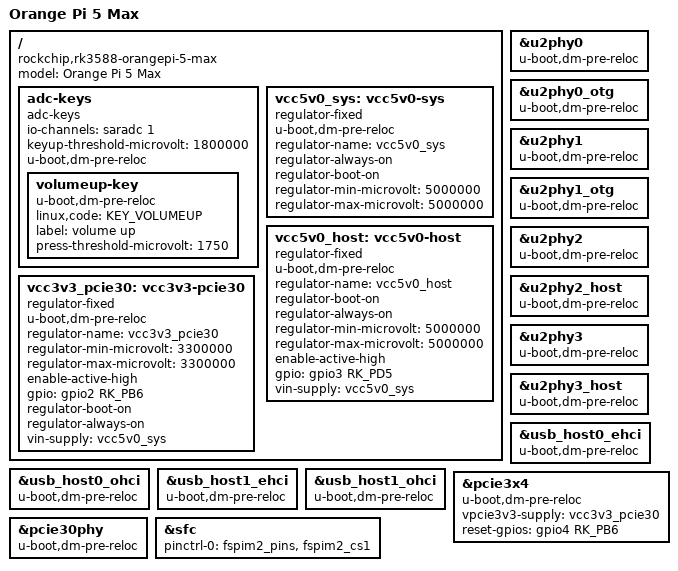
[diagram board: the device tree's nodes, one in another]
// SPDX-License-Identifier: (GPL-2.0+ OR MIT)
/*
 * Copyright (c) 2021 Rockchip Electronics Co., Ltd
 *
 */

/dts-v1/;
#include "rk3588.dtsi"
#include "rk3588-u-boot.dtsi"
#include <dt-bindings/input/input.h>

/ {
	model = "Orange Pi 5 Max";
	compatible = "rockchip,rk3588-orangepi-5-max", "rockchip,rk3588";

	adc-keys {
		compatible = "adc-keys";
		io-channels = <&saradc 1>;
		io-channel-names = "buttons";
		keyup-threshold-microvolt = <1800000>;
		u-boot,dm-pre-reloc;
		status = "okay";

		volumeup-key {
			u-boot,dm-pre-reloc;
			linux,code = <KEY_VOLUMEUP>;
			label = "volume up";
			press-threshold-microvolt = <1750>;
		};
	};

	vcc5v0_sys: vcc5v0-sys {
		u-boot,dm-pre-reloc;
		compatible = "regulator-fixed";
		regulator-name = "vcc5v0_sys";
		regulator-always-on;
		regulator-boot-on;
		regulator-min-microvolt = <5000000>;
		regulator-max-microvolt = <5000000>;
	};

	vcc5v0_host: vcc5v0-host {
		u-boot,dm-pre-reloc;
		compatible = "regulator-fixed";
		regulator-name = "vcc5v0_host";
		regulator-boot-on;
		regulator-always-on;
		regulator-min-microvolt = <5000000>;
		regulator-max-microvolt = <5000000>;
		enable-active-high;
		gpio = <&gpio3 RK_PD5 GPIO_ACTIVE_HIGH>;
		vin-supply = <&vcc5v0_sys>;
	};

	vcc3v3_pcie30: vcc3v3-pcie30 {
		u-boot,dm-pre-reloc;
		compatible = "regulator-fixed";
		regulator-name = "vcc3v3_pcie30";
		regulator-min-microvolt = <3300000>;
		regulator-max-microvolt = <3300000>;
		enable-active-high;
		gpio = <&gpio2 RK_PB6 GPIO_ACTIVE_HIGH>;
		regulator-boot-on;
		regulator-always-on;
		vin-supply = <&vcc5v0_sys>;
	};
};

&u2phy0 {
	u-boot,dm-pre-reloc;
	status = "okay";
};

&u2phy0_otg {
	u-boot,dm-pre-reloc;
	status = "okay";
};

&u2phy1 {
	u-boot,dm-pre-reloc;
	status = "okay";
};

&u2phy1_otg {
	u-boot,dm-pre-reloc;
	status = "okay";
};

&u2phy2 {
	u-boot,dm-pre-reloc;
	status = "okay";
};

&u2phy2_host {
	u-boot,dm-pre-reloc;
	status = "okay";
};

&u2phy3 {
	u-boot,dm-pre-reloc;
	status = "okay";
};

&u2phy3_host {
	u-boot,dm-pre-reloc;
	status = "okay";
};

&usb_host0_ehci {
	u-boot,dm-pre-reloc;
	status = "okay";
};

&usb_host0_ohci {
	u-boot,dm-pre-reloc;
	status = "okay";
};

&usb_host1_ehci {
	u-boot,dm-pre-reloc;
	status = "okay";
};

&usb_host1_ohci {
	u-boot,dm-pre-reloc;
	status = "okay";
};

&pcie3x4 {
	u-boot,dm-pre-reloc;
	vpcie3v3-supply = <&vcc3v3_pcie30>;
	reset-gpios = <&gpio4 RK_PB6 GPIO_ACTIVE_HIGH>;
	status = "okay";
};

&pcie30phy {
	u-boot,dm-pre-reloc;
	status = "okay";
};

&sfc {
	pinctrl-names = "default";
	pinctrl-0 = <&fspim2_pins &fspim2_cs1>;

};
